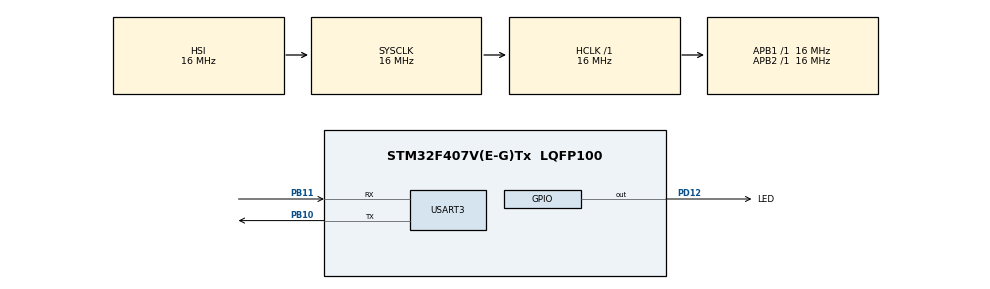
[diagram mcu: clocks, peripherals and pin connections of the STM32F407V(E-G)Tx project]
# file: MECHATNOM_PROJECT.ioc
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Dma.Request0=USART3_RX
Dma.USART3_RX.0.Direction=DMA_PERIPH_TO_MEMORY
Dma.USART3_RX.0.FIFOMode=DMA_FIFOMODE_DISABLE
Dma.USART3_RX.0.Instance=DMA1_Stream1
Dma.USART3_RX.0.MemDataAlignment=DMA_MDATAALIGN_BYTE
Dma.USART3_RX.0.MemInc=DMA_MINC_ENABLE
Dma.USART3_RX.0.Mode=DMA_NORMAL
Dma.USART3_RX.0.PeriphDataAlignment=DMA_PDATAALIGN_BYTE
Dma.USART3_RX.0.PeriphInc=DMA_PINC_DISABLE
Dma.USART3_RX.0.Priority=DMA_PRIORITY_LOW
Mcu.Family=STM32F4
Mcu.Name=STM32F407V(E-G)Tx
Mcu.Package=LQFP100
NVIC.DMA1_Stream1_IRQn=true\:0\:0\:false\:false\:true\:false\:true\:true
NVIC.PriorityGroup=NVIC_PRIORITYGROUP_4
NVIC.USART3_IRQn=true\:0\:0\:false\:false\:true\:true\:true\:true
PB10.Mode=Asynchronous
PB10.Signal=USART3_TX
PB11.Mode=Asynchronous
PB11.Signal=USART3_RX
PD12.GPIO_Label=LED
PD12.Signal=GPIO_Output
ProjectManager.HeapSize=0x200
ProjectManager.StackSize=0x400
ProjectManager.TargetToolchain=TrueSTUDIO
RCC.AHBFreq_Value=16000000
RCC.APB1Freq_Value=16000000
RCC.APB2Freq_Value=16000000
RCC.CortexFreq_Value=16000000
RCC.HSE_VALUE=25000000
RCC.HSI_VALUE=16000000
RCC.LSE_VALUE=32768
RCC.SYSCLKFreq_VALUE=16000000
RCC.VCOOutputFreq_Value=192000000
USART3.VirtualMode=VM_ASYNC
board=custom

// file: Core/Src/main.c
/* USER CODE BEGIN Header */
/**
 ******************************************************************************
 * @file           : main.c
 * @brief          : Main program body
 ******************************************************************************
 * @attention
 *
 * Copyright (c) 2022 STMicroelectronics.
 * All rights reserved.
 *
 * This software is licensed under terms that can be found in the LICENSE file
 * in the root directory of this software component.
 * If no LICENSE file comes with this software, it is provided AS-IS.
 *
 ******************************************************************************
 */
/* USER CODE END Header */
#include "main.h"
#include "dma.h"
#include "usart.h"
#include "gpio.h"

/* USER CODE BEGIN Includes */
#include <stdbool.h>
#include <string.h>
/* USER CODE END Includes */

/* USER CODE BEGIN PD */
#define LEDON    "ledon"
#define LEDOFF   "ledoff"
#define START    "start"
#define STOP     "stop"
#define LEDSTART "ledstart"
/* USER CODE END PD */

/* USER CODE BEGIN PV */
extern DMA_HandleTypeDef hdma_usart3_rx;
stSoftTimer_t stTimer;
stUART_t stUART3;
/* USER CODE END PV */

void SystemClock_Config(void);

/* USER CODE BEGIN 0 */
void HAL_UARTEx_RxEventCallback(UART_HandleTypeDef *huart, uint16_t Size) {
	if (huart->Instance == USART3) {
		HAL_UARTEx_ReceiveToIdle_DMA(&huart3, stUART3.buffer, RXBUFF_SIZE);
		__HAL_DMA_DISABLE_IT(&hdma_usart3_rx, DMA_IT_HT);
		stUART3.size = Size;
		for (int i = Size; i < RXBUFF_SIZE; i++) {
			stUART3.buffer[i] = 0;
		}
		stUART3.update = true;
		if (stUART3.echo == true) {
			HAL_UART_Transmit(&huart3, (uint8_t *) stUART3.buffer, stUART3.size,
					200);
		}
	}
}
void Task_UART() {
	char buffer[RXBUFF_SIZE];
	strcpy(buffer, stUART3.buffer);
	char* data = strchr(buffer, '=') + 1;
	char* command = strtok(buffer, "=");

	if (!strcmp(command, LEDON)) {
		stTimer.period_On = atoi(data);
	} else if (!strcmp(command, LEDOFF)) {
		stTimer.period_Off = atoi(data);
	} else if (!strcmp(command, START)) {
		stUART3.echo = true;
	} else if (!strcmp(command, STOP)) {
		stUART3.echo = false;
		stTimer.period_On = 1000;
		stTimer.period_Off = 1000;
	} else if (!strcmp(command, LEDSTART)) {
		stTimer.periodState = timerPeriodState_On;
	}
}
void Toggle_Led() {
	if (stTimer.periodState == timerPeriodState_Off) {
		HAL_GPIO_WritePin(LED_GPIO_Port, LED_Pin, GPIO_PIN_RESET);
		if (stTimer.count == stTimer.period_Off) {
			stTimer.count = 0;
			stTimer.periodState = timerPeriodState_On;
		}
	} else if (stTimer.periodState == timerPeriodState_On) {
		HAL_GPIO_WritePin(LED_GPIO_Port, LED_Pin, GPIO_PIN_SET);
		if (stTimer.count == stTimer.period_On) {
			stTimer.count = 0;
			stTimer.periodState = timerPeriodState_Off;
		}
	}
}
void Systick_Init() {
	HAL_SYSTICK_Config(HAL_RCC_GetHCLKFreq() / 1000);
	HAL_SYSTICK_CLKSourceConfig(SYSTICK_CLKSOURCE_HCLK);
	HAL_NVIC_SetPriority(SysTick_IRQn, 0, 0);
}
/* USER CODE END 0 */

int main(void) {

	/* MCU Configuration--------------------------------------------------------*/

	/* Reset of all peripherals, Initializes the Flash interface and the Systick. */
	HAL_Init();

	/* Configure the system clock */
	SystemClock_Config();

	/* Initialize all configured peripherals */
	MX_GPIO_Init();
	MX_DMA_Init();
	MX_USART3_UART_Init();
	/* USER CODE BEGIN 2 */
	Systick_Init();
	HAL_UARTEx_ReceiveToIdle_DMA(&huart3, stUART3.buffer, RXBUFF_SIZE);
	__HAL_DMA_DISABLE_IT(&hdma_usart3_rx, DMA_IT_HT);
	stTimer.period_On = 500;
	stTimer.period_Off = 500;
	/* USER CODE END 2 */

	/* Infinite loop */
	while (1) {
		if (stUART3.update == true) {
			Task_UART();
			stUART3.update = false;
		}
		Toggle_Led();
	}
}

void SystemClock_Config(void) {
	RCC_OscInitTypeDef RCC_OscInitStruct = { 0 };
	RCC_ClkInitTypeDef RCC_ClkInitStruct = { 0 };

	/** Configure the main internal regulator output voltage
	 */
	__HAL_RCC_PWR_CLK_ENABLE()
	;
	__HAL_PWR_VOLTAGESCALING_CONFIG(PWR_REGULATOR_VOLTAGE_SCALE1);

	/** Initializes the RCC Oscillators according to the specified parameters
	 * in the RCC_OscInitTypeDef structure.
	 */
	RCC_OscInitStruct.OscillatorType = RCC_OSCILLATORTYPE_HSI;
	RCC_OscInitStruct.HSIState = RCC_HSI_ON;
	RCC_OscInitStruct.HSICalibrationValue = RCC_HSICALIBRATION_DEFAULT;
	RCC_OscInitStruct.PLL.PLLState = RCC_PLL_NONE;
	if (HAL_RCC_OscConfig(&RCC_OscInitStruct) != HAL_OK) {
		Error_Handler();
	}

	/** Initializes the CPU, AHB and APB buses clocks
	 */
	RCC_ClkInitStruct.ClockType = RCC_CLOCKTYPE_HCLK | RCC_CLOCKTYPE_SYSCLK
			| RCC_CLOCKTYPE_PCLK1 | RCC_CLOCKTYPE_PCLK2;
	RCC_ClkInitStruct.SYSCLKSource = RCC_SYSCLKSOURCE_HSI;
	RCC_ClkInitStruct.AHBCLKDivider = RCC_SYSCLK_DIV1;
	RCC_ClkInitStruct.APB1CLKDivider = RCC_HCLK_DIV1;
	RCC_ClkInitStruct.APB2CLKDivider = RCC_HCLK_DIV1;

	if (HAL_RCC_ClockConfig(&RCC_ClkInitStruct, FLASH_LATENCY_0) != HAL_OK) {
		Error_Handler();
	}
}

void Error_Handler(void) {
	__disable_irq();
	while (1) {
	}
}
